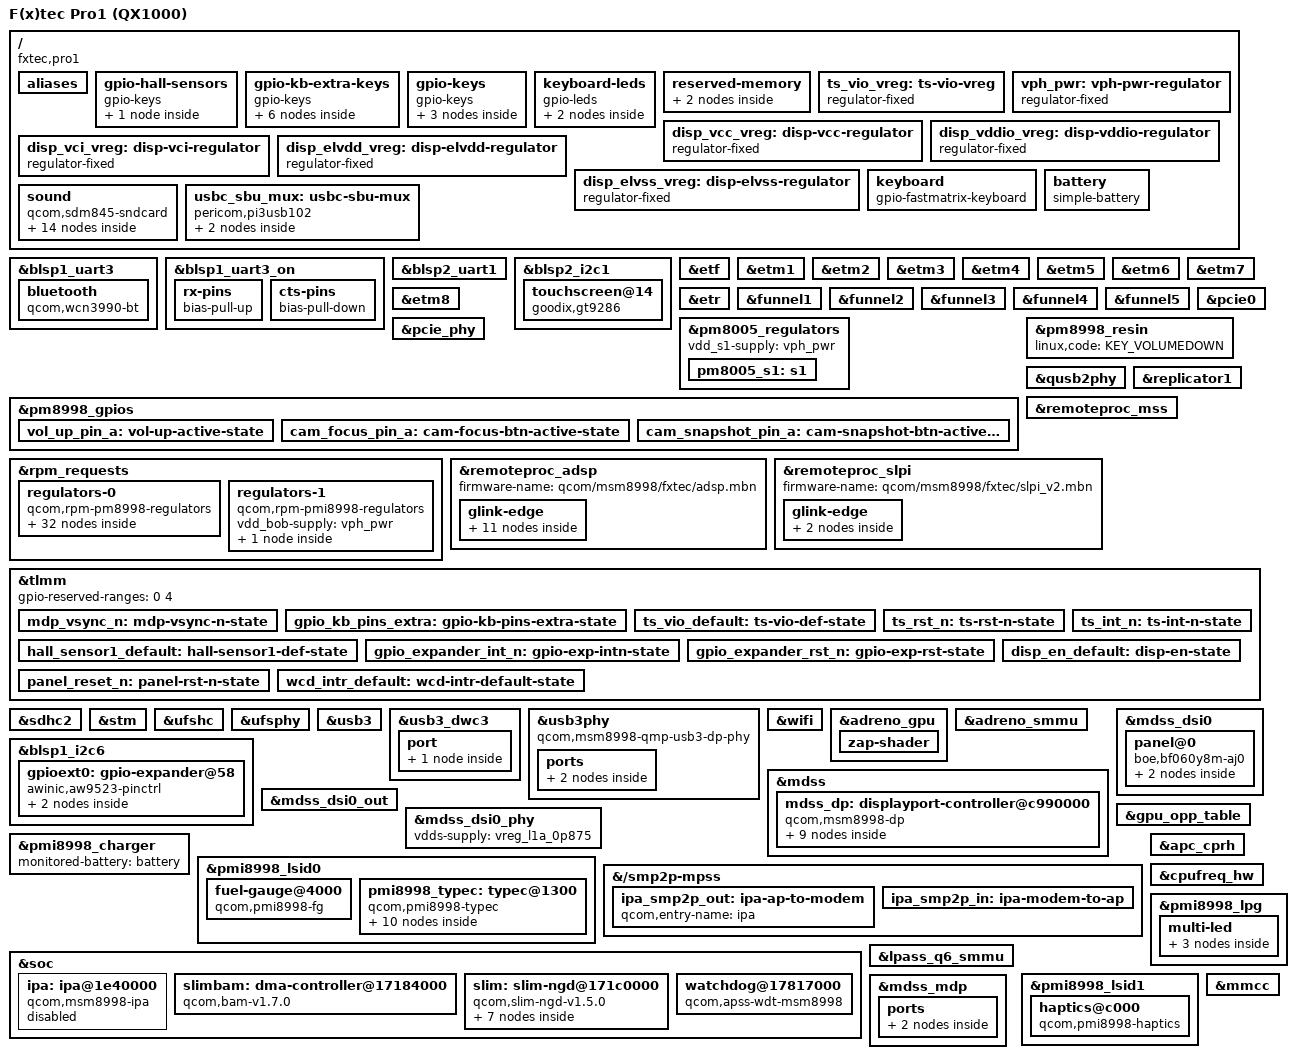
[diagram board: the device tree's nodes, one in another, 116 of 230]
// SPDX-License-Identifier: BSD-3-Clause
/*
 * Copyright (c) 2021, AngeloGioacchino Del Regno
 *                     <angelogioacchino.delregno@somainline.org>
 */

/dts-v1/;

#include <dt-bindings/input/input.h>
#include <dt-bindings/leds/common.h>
#include <dt-bindings/pinctrl/qcom,pmic-gpio.h>
#include "msm8998.dtsi"
#include "pm8005.dtsi"
#include "pm8998.dtsi"
#include "pmi8998.dtsi"

/ {
	model = "F(x)tec Pro1 (QX1000)";
	compatible = "fxtec,pro1", "qcom,msm8998";
	chassis-type = "handset";
	qcom,board-id = <0x02000b 0x10>;

	aliases {
		serial0 = &blsp2_uart1;
		serial1 = &blsp1_uart3;
	};

	/*
	 * Until we hook up type-c detection, we
	 * have to stick with this. But it works.
	 */
	extcon_usb: extcon-usb {
		compatible = "linux,extcon-usb-gpio";
		id-gpios = <&tlmm 38 GPIO_ACTIVE_HIGH>;
	};

	gpio-hall-sensors {
		compatible = "gpio-keys";
		label = "Hall sensors";
		pinctrl-names = "default";
		pinctrl-0 = <&hall_sensor1_default>;

		event-hall-sensor1 {
			label = "Keyboard Hall Sensor";
			gpios = <&tlmm 124 GPIO_ACTIVE_HIGH>;
			debounce-interval = <15>;
			wakeup-source;
			linux,input-type = <EV_SW>;
			linux,code = <SW_KEYPAD_SLIDE>;
		};
	};

	gpio-kb-extra-keys {
		compatible = "gpio-keys";
		label = "Keyboard extra keys";
		pinctrl-names = "default";
		pinctrl-0 = <&gpio_kb_pins_extra>;

		key-home {
			label = "Home";
			gpios = <&tlmm 21 GPIO_ACTIVE_LOW>;
			linux,code = <KEY_HOMEPAGE>;
			debounce-interval = <15>;
			linux,can-disable;
		};

		key-super-l {
			label = "Super Left";
			gpios = <&tlmm 32 GPIO_ACTIVE_LOW>;
			linux,code = <KEY_FN>;
			debounce-interval = <15>;
			linux,can-disable;
		};

		key-super-r {
			label = "Super Right";
			gpios = <&tlmm 33 GPIO_ACTIVE_LOW>;
			linux,code = <KEY_FN>;
			debounce-interval = <15>;
			linux,can-disable;
		};

		key-shift {
			label = "Shift";
			gpios = <&tlmm 114 GPIO_ACTIVE_LOW>;
			linux,code = <KEY_RIGHTSHIFT>;
			debounce-interval = <15>;
			linux,can-disable;
		};

		key-ctrl {
			label = "Ctrl";
			gpios = <&tlmm 128 GPIO_ACTIVE_LOW>;
			linux,code = <KEY_LEFTCTRL>;
			debounce-interval = <15>;
			linux,can-disable;
		};

		key-alt {
			label = "Alt";
			gpios = <&tlmm 129 GPIO_ACTIVE_LOW>;
			linux,code = <KEY_LEFTALT>;
			debounce-interval = <15>;
			linux,can-disable;
		};
	};

	gpio-keys {
		compatible = "gpio-keys";
		label = "Side buttons";
		pinctrl-names = "default";
		pinctrl-0 = <&vol_up_pin_a>, <&cam_focus_pin_a>,
			    <&cam_snapshot_pin_a>;
		button-vol-up {
			label = "Volume Up";
			gpios = <&pm8998_gpios 6 GPIO_ACTIVE_LOW>;
			linux,input-type = <EV_KEY>;
			linux,code = <KEY_VOLUMEUP>;
			wakeup-source;
			debounce-interval = <15>;
		};

		button-camera-snapshot {
			label = "Camera Snapshot";
			gpios = <&pm8998_gpios 7 GPIO_ACTIVE_LOW>;
			linux,input-type = <EV_KEY>;
			linux,code = <KEY_CAMERA>;
			debounce-interval = <15>;
		};

		button-camera-focus {
			label = "Camera Focus";
			gpios = <&pm8998_gpios 8 GPIO_ACTIVE_LOW>;
			linux,input-type = <EV_KEY>;
			linux,code = <KEY_CAMERA_FOCUS>;
			debounce-interval = <15>;
		};
	};

	keyboard-leds {
		compatible = "gpio-leds";

		led-0 {
			color = <LED_COLOR_ID_WHITE>;
			default-state = "off";
			function = LED_FUNCTION_KBD_BACKLIGHT;
			gpios = <&tlmm 16 GPIO_ACTIVE_HIGH>;
			label = "white:kbd_backlight";
			retain-state-suspended;
		};

		led-1 {
			color = <LED_COLOR_ID_YELLOW>;
			default-state = "off";
			function = LED_FUNCTION_CAPSLOCK;
			gpios = <&tlmm 26 GPIO_ACTIVE_HIGH>;
			label = "yellow:capslock";
			linux,default-trigger = "kbd-capslock";
		};
	};

	reserved-memory {
		cont_splash_mem: memory@9d400000 {
			reg = <0x0 0x9d400000 0x0 0x2000000>;
			no-map;
		};

		zap_shader_region: memory@f6400000 {
			compatible = "shared-dma-pool";
			reg = <0x0 0xf6400000 0x0 0x2000>;
			no-map;
		};

		ramoops@ffc00000 {
			compatible = "ramoops";
			reg = <0x0 0xffc00000 0x0 0x100000>;
			console-size = <0x60000>;
			ecc-size = <16>;
			ftrace-size = <0x10000>;
			pmsg-size = <0x20000>;
			record-size = <0x10000>;
		};
	};

	ts_vio_vreg: ts-vio-vreg {
		compatible = "regulator-fixed";
		regulator-name = "ts_vio_reg";
		startup-delay-us = <2>;
		enable-active-high;
		gpio = <&tlmm 81 GPIO_ACTIVE_HIGH>;
		pinctrl-names = "default";
		pinctrl-0 = <&ts_vio_default>;
		regulator-always-on;
	};

	vph_pwr: vph-pwr-regulator {
		compatible = "regulator-fixed";
		regulator-name = "vph_pwr";
		regulator-always-on;
		regulator-boot-on;
	};
};

&blsp1_uart3 {
	status = "okay";

	bluetooth {
		compatible = "qcom,wcn3990-bt";

		vddio-supply = <&vreg_s4a_1p8>;
		vddxo-supply = <&vreg_l7a_1p8>;
		vddrf-supply = <&vreg_l17a_1p3>;
		vddch0-supply = <&vreg_l25a_3p3>;
		max-speed = <3200000>;
	};
};

&blsp1_uart3_on {
	rx-pins {
		/delete-property/ bias-disable;
		/*
		 * Configure a pull-up on 45 (RX). This is needed to
		 * avoid garbage data when the TX pin of the Bluetooth
		 * module is in tri-state (module powered off or not
		 * driving the signal yet).
		 */
		bias-pull-up;
	};

	cts-pins {
		/delete-property/ bias-disable;
		/*
		 * Configure a pull-down on 47 (CTS) to match the pull
		 * of the Bluetooth module.
		 */
		bias-pull-down;
	};
};

&blsp2_uart1 {
	status = "okay";
};

&blsp2_i2c1 {
	status = "okay";

	touchscreen@14 {
		compatible = "goodix,gt9286";
		reg = <0x14>;
		interrupt-parent = <&tlmm>;
		interrupts = <125 IRQ_TYPE_LEVEL_LOW>;
		reset-gpios = <&tlmm 89 GPIO_ACTIVE_LOW>;
		AVDD28-supply = <&vreg_l28_3p0>;
		VDDIO-supply = <&ts_vio_vreg>;
		pinctrl-names = "active";
		pinctrl-0 = <&ts_rst_n>, <&ts_int_n>;
	};
};

&etf {
	status = "okay";
};

&etm1 {
	status = "okay";
};

&etm2 {
	status = "okay";
};

&etm3 {
	status = "okay";
};

&etm4 {
	status = "okay";
};

&etm5 {
	status = "okay";
};

&etm6 {
	status = "okay";
};

&etm7 {
	status = "okay";
};

&etm8 {
	status = "okay";
};

&etr {
	status = "okay";
};

&funnel1 {
	status = "okay";
};

&funnel2 {
	status = "okay";
};

&funnel3 {
	status = "okay";
};

&funnel4 {
	/* FIXME: Figure out why clock late_initcall crashes the board with this enabled. */
};

&funnel5 {
	/* FIXME: Figure out why clock late_initcall crashes the board with this enabled. */
};

&pcie0 {
	status = "okay";
};

&pcie_phy {
	status = "okay";
};

&pm8005_regulators {
	vdd_s1-supply = <&vph_pwr>;

	pm8005_s1: s1 { /* VDD_GFX supply */
		regulator-min-microvolt = <524000>;
		regulator-max-microvolt = <1100000>;
		regulator-enable-ramp-delay = <500>;

		/* Hack until we rig up the gpu consumer */
		regulator-always-on;
	};
};

&pm8998_gpios {
	vol_up_pin_a: vol-up-active-state {
		pins = "gpio6";
		function = "normal";
		bias-pull-up;
		input-enable;
		qcom,drive-strength = <PMIC_GPIO_STRENGTH_NO>;
	};

	cam_focus_pin_a: cam-focus-btn-active-state {
		pins = "gpio7";
		function = "normal";
		bias-pull-up;
		input-enable;
		qcom,drive-strength = <PMIC_GPIO_STRENGTH_NO>;
	};

	cam_snapshot_pin_a: cam-snapshot-btn-active-state {
		pins = "gpio8";
		function = "normal";
		bias-pull-up;
		input-enable;
		qcom,drive-strength = <PMIC_GPIO_STRENGTH_NO>;
	};
};

&pm8998_resin {
	linux,code = <KEY_VOLUMEDOWN>;
	status = "okay";
};

&qusb2phy {
	status = "okay";

	vdd-supply = <&vreg_l1a_0p875>;
	vdda-pll-supply = <&vreg_l12a_1p8>;
	vdda-phy-dpdm-supply = <&vreg_l24a_3p075>;
};

&replicator1 {
	status = "okay";
};

&rpm_requests {
	regulators-0 {
		compatible = "qcom,rpm-pm8998-regulators";

		vdd_s1-supply = <&vph_pwr>;
		vdd_s2-supply = <&vph_pwr>;
		vdd_s3-supply = <&vph_pwr>;
		vdd_s4-supply = <&vph_pwr>;
		vdd_s5-supply = <&vph_pwr>;
		vdd_s6-supply = <&vph_pwr>;
		vdd_s7-supply = <&vph_pwr>;
		vdd_s8-supply = <&vph_pwr>;
		vdd_s9-supply = <&vph_pwr>;
		vdd_s10-supply = <&vph_pwr>;
		vdd_s11-supply = <&vph_pwr>;
		vdd_s12-supply = <&vph_pwr>;
		vdd_s13-supply = <&vph_pwr>;
		vdd_l1_l27-supply = <&vreg_s7a_1p025>;
		vdd_l2_l8_l17-supply = <&vreg_s3a_1p35>;
		vdd_l3_l11-supply = <&vreg_s7a_1p025>;
		vdd_l4_l5-supply = <&vreg_s7a_1p025>;
		vdd_l6-supply = <&vreg_s5a_2p04>;
		vdd_l7_l12_l14_l15-supply = <&vreg_s5a_2p04>;
		vdd_l9-supply = <&vreg_bob>;
		vdd_l10_l23_l25-supply = <&vreg_bob>;
		vdd_l13_l19_l21-supply = <&vreg_bob>;
		vdd_l16_l28-supply = <&vreg_bob>;
		vdd_l18_l22-supply = <&vreg_bob>;
		vdd_l20_l24-supply = <&vreg_bob>;
		vdd_l26-supply = <&vreg_s3a_1p35>;
		vdd_lvs1_lvs2-supply = <&vreg_s4a_1p8>;

		vreg_s3a_1p35: s3 {
			regulator-min-microvolt = <1352000>;
			regulator-max-microvolt = <1352000>;
		};

		vreg_s4a_1p8: s4 {
			regulator-min-microvolt = <1800000>;
			regulator-max-microvolt = <1800000>;
			regulator-allow-set-load;
		};

		vreg_s5a_2p04: s5 {
			regulator-min-microvolt = <1904000>;
			regulator-max-microvolt = <2040000>;
		};

		vreg_s7a_1p025: s7 {
			regulator-min-microvolt = <900000>;
			regulator-max-microvolt = <1028000>;
		};

		vreg_l1a_0p875: l1 {
			regulator-min-microvolt = <880000>;
			regulator-max-microvolt = <880000>;
		};

		vreg_l2a_1p2: l2 {
			regulator-min-microvolt = <1200000>;
			regulator-max-microvolt = <1200000>;
		};

		vreg_l3a_1p0: l3 {
			regulator-min-microvolt = <1000000>;
			regulator-max-microvolt = <1000000>;
		};

		vreg_l5a_0p8: l5 {
			regulator-min-microvolt = <800000>;
			regulator-max-microvolt = <800000>;
		};

		vreg_l6a_1p8: l6 {
			regulator-min-microvolt = <1808000>;
			regulator-max-microvolt = <1808000>;
		};

		vreg_l7a_1p8: l7 {
			regulator-min-microvolt = <1800000>;
			regulator-max-microvolt = <1800000>;
		};

		vreg_l8a_1p2: l8 {
			regulator-min-microvolt = <1200000>;
			regulator-max-microvolt = <1200000>;
		};

		vreg_l9a_1p8: l9 {
			regulator-min-microvolt = <1808000>;
			regulator-max-microvolt = <2960000>;
		};

		vreg_l10a_1p8: l10 {
			regulator-min-microvolt = <1808000>;
			regulator-max-microvolt = <2960000>;
		};

		vreg_l11a_1p0: l11 {
			regulator-min-microvolt = <1000000>;
			regulator-max-microvolt = <1000000>;
		};

		vreg_l12a_1p8: l12 {
			regulator-min-microvolt = <1800000>;
			regulator-max-microvolt = <1800000>;
		};

		vreg_l13a_2p95: l13 {
			regulator-min-microvolt = <1808000>;
			regulator-max-microvolt = <2960000>;
		};

		vreg_l14a_1p88: l14 {
			regulator-min-microvolt = <1880000>;
			regulator-max-microvolt = <1880000>;
		};

		vreg_l15a_1p8: l15 {
			regulator-min-microvolt = <1800000>;
			regulator-max-microvolt = <1800000>;
		};

		vreg_l16a_2p7: l16 {
			regulator-min-microvolt = <2704000>;
			regulator-max-microvolt = <2704000>;
		};

		vreg_l17a_1p3: l17 {
			regulator-min-microvolt = <1304000>;
			regulator-max-microvolt = <1304000>;
		};

		vreg_l18a_2p7: l18 {
			regulator-min-microvolt = <2704000>;
			regulator-max-microvolt = <2704000>;
		};

		vreg_l19a_3p0: l19 {
			regulator-min-microvolt = <3008000>;
			regulator-max-microvolt = <3008000>;
		};

		vreg_l20a_2p95: l20 {
			regulator-min-microvolt = <2960000>;
			regulator-max-microvolt = <2960000>;
			regulator-allow-set-load;
		};

		vreg_l21a_2p95: l21 {
			regulator-min-microvolt = <2960000>;
			regulator-max-microvolt = <2960000>;
			regulator-system-load = <800000>;
			regulator-allow-set-load;
		};

		vreg_l22a_2p85: l22 {
			regulator-min-microvolt = <2864000>;
			regulator-max-microvolt = <2864000>;
		};

		vreg_l23a_3p3: l23 {
			regulator-min-microvolt = <3312000>;
			regulator-max-microvolt = <3312000>;
		};

		vreg_l24a_3p075: l24 {
			regulator-min-microvolt = <3088000>;
			regulator-max-microvolt = <3088000>;
		};

		vreg_l25a_3p3: l25 {
			regulator-min-microvolt = <3104000>;
			regulator-max-microvolt = <3312000>;
		};

		vreg_l26a_1p2: l26 {
			regulator-min-microvolt = <1200000>;
			regulator-max-microvolt = <1200000>;
			regulator-allow-set-load;
		};

		vreg_l28_3p0: l28 {
			regulator-min-microvolt = <3008000>;
			regulator-max-microvolt = <3008000>;
		};

		vreg_lvs1a_1p8: lvs1 {
			regulator-min-microvolt = <1800000>;
			regulator-max-microvolt = <1800000>;
		};

		vreg_lvs2a_1p8: lvs2 {
			regulator-min-microvolt = <1800000>;
			regulator-max-microvolt = <1800000>;
		};

	};

	regulators-1 {
		compatible = "qcom,rpm-pmi8998-regulators";

		vdd_bob-supply = <&vph_pwr>;

		vreg_bob: bob {
			regulator-min-microvolt = <3312000>;
			regulator-max-microvolt = <3600000>;
		};
	};
};

&remoteproc_adsp {
	status = "okay";
};

&remoteproc_mss {
	status = "okay";
};

&remoteproc_slpi {
	status = "okay";
};

&tlmm {
	gpio-reserved-ranges = <0 4>;

	mdp_vsync_n: mdp-vsync-n-state {
		pins = "gpio10";
		function = "mdp_vsync_a";
		bias-pull-down;
		drive-strength = <2>;
	};

	gpio_kb_pins_extra: gpio-kb-pins-extra-state {
		pins = "gpio21", "gpio32", "gpio33", "gpio114",
		       "gpio128", "gpio129";
		function = "gpio";
		drive-strength = <2>;
		bias-pull-up;
	};

	ts_vio_default: ts-vio-def-state {
		pins = "gpio81";
		function = "gpio";
		bias-disable;
		drive-strength = <2>;
	};

	ts_rst_n: ts-rst-n-state {
		pins = "gpio89";
		function = "gpio";
		bias-pull-up;
		drive-strength = <8>;
	};

	hall_sensor1_default: hall-sensor1-def-state {
		pins = "gpio124";
		function = "gpio";
		bias-disable;
		drive-strength = <2>;
	};

	ts_int_n: ts-int-n-state {
		pins = "gpio125";
		function = "gpio";
		bias-disable;
		drive-strength = <8>;
	};
};

&sdhc2 {
	status = "okay";
	cd-gpios = <&tlmm 95 GPIO_ACTIVE_LOW>;

	vmmc-supply = <&vreg_l21a_2p95>;
	vqmmc-supply = <&vreg_l13a_2p95>;

	pinctrl-names = "default", "sleep";
	pinctrl-0 = <&sdc2_on &sdc2_cd>;
	pinctrl-1 = <&sdc2_off &sdc2_cd>;
};

&stm {
	status = "okay";
};

&ufshc {
	status = "okay";
	vcc-supply = <&vreg_l20a_2p95>;
	vccq-supply = <&vreg_l26a_1p2>;
	vccq2-supply = <&vreg_s4a_1p8>;
	vdd-hba-supply = <&vreg_l26a_1p2>;
	vcc-max-microamp = <750000>;
	vccq-max-microamp = <560000>;
	vccq2-max-microamp = <750000>;
};

&ufsphy {
	status = "okay";
	vdda-phy-supply = <&vreg_l1a_0p875>;
	vdda-pll-supply = <&vreg_l2a_1p2>;
};

&usb3 {
	status = "okay";
};

&usb3_dwc3 {
	dr_mode = "peripheral";
	extcon = <&extcon_usb>;
};

&usb3phy {
	status = "okay";

	vdda-phy-supply = <&vreg_l1a_0p875>;
	vdda-pll-supply = <&vreg_l2a_1p2>;
};

/* GT9286 analog supply */
&vreg_l28_3p0 {
	regulator-min-microvolt = <2800000>;
	regulator-max-microvolt = <2800000>;
};

&wifi {
	status = "okay";

	vdd-0.8-cx-mx-supply = <&vreg_l5a_0p8>;
	vdd-1.8-xo-supply = <&vreg_l7a_1p8>;
	vdd-1.3-rfa-supply = <&vreg_l17a_1p3>;
	vdd-3.3-ch0-supply = <&vreg_l25a_3p3>;
};

/*
 * Pro1 additions on top of mainline msm8998-fxtec-pro1.dts:
 * display (BOE BF060Y8M-AJ0 on DSI0), Adreno 540, hardware keyboard
 * (AW9523B expander + gpio-fastmatrix), remoteproc firmware paths.
 * Forward-ported from gitlab.com/msm8998-mainline/linux (master).
 */

/ {
	/* Panel rails are switched on by the bootloader and never touched again */
	disp_vcc_vreg: disp-vcc-regulator {
		compatible = "regulator-fixed";
		regulator-name = "disp_vcc";
		regulator-min-microvolt = <3300000>;
		regulator-max-microvolt = <3300000>;
		regulator-boot-on;
		regulator-always-on;
	};

	disp_vddio_vreg: disp-vddio-regulator {
		compatible = "regulator-fixed";
		regulator-name = "disp_vddio";
		regulator-min-microvolt = <1800000>;
		regulator-max-microvolt = <1800000>;
		regulator-boot-on;
		regulator-always-on;
	};

	disp_vci_vreg: disp-vci-regulator {
		compatible = "regulator-fixed";
		regulator-name = "disp_vci";
		regulator-min-microvolt = <3000000>;
		regulator-max-microvolt = <3000000>;
		regulator-boot-on;
		regulator-always-on;
	};

	disp_elvdd_vreg: disp-elvdd-regulator {
		compatible = "regulator-fixed";
		regulator-name = "disp_elvdd";
		regulator-min-microvolt = <4600000>;
		regulator-max-microvolt = <4600000>;
		regulator-boot-on;
		regulator-always-on;
	};

	disp_elvss_vreg: disp-elvss-regulator {
		compatible = "regulator-fixed";
		regulator-name = "disp_elvss";
		regulator-min-microvolt = <2400000>;
		regulator-max-microvolt = <2400000>;
		regulator-boot-on;
		regulator-always-on;
	};

	keyboard {
		compatible = "gpio-fastmatrix-keyboard";
		label = "F(x)tec Pro1 Hardware Keyboard";

		row-gpios = <&gpioext0 0 (GPIO_ACTIVE_LOW | GPIO_OPEN_DRAIN)>,
			    <&gpioext0 1 (GPIO_ACTIVE_LOW | GPIO_OPEN_DRAIN)>,
			    <&gpioext0 2 (GPIO_ACTIVE_LOW | GPIO_OPEN_DRAIN)>,
			    <&gpioext0 3 (GPIO_ACTIVE_LOW | GPIO_OPEN_DRAIN)>,
			    <&gpioext0 4 (GPIO_ACTIVE_LOW | GPIO_OPEN_DRAIN)>,
			    <&gpioext0 5 (GPIO_ACTIVE_LOW | GPIO_OPEN_DRAIN)>,
			    <&gpioext0 6 (GPIO_ACTIVE_LOW | GPIO_OPEN_DRAIN)>,
			    <&gpioext0 7 (GPIO_ACTIVE_LOW | GPIO_OPEN_DRAIN)>;
		col-gpios = <&gpioext0 8 GPIO_ACTIVE_LOW>,
			    <&gpioext0 9 GPIO_ACTIVE_LOW>,
			    <&gpioext0 10 GPIO_ACTIVE_LOW>,
			    <&gpioext0 11 GPIO_ACTIVE_LOW>,
			    <&gpioext0 12 GPIO_ACTIVE_LOW>,
			    <&gpioext0 13 GPIO_ACTIVE_LOW>,
			    <&gpioext0 14 GPIO_ACTIVE_LOW>,
			    <&gpioext0 15 GPIO_ACTIVE_LOW>;

		pinctrl-names = "default";
		pinctrl-0 = <&keyboard_pins_col>, <&keyboard_pins_row>;

		/*
		 * A change is reported once two consecutive scans agree, so the time to
		 * register a press is ~2 x (debounce + scan). With 1500 us per column
		 * (12 ms per scan) a fast tap fell between scans and was dropped; the
		 * AW9523 I2C round trips already give each column a few hundred us.
		 */
		autorescan-ms = <5>;
		debounce-delay-ms = <2>;
		col-scan-delay-us = <100>;

		linux,keymap = <
			MATRIX_KEY(0, 0, KEY_F1)	MATRIX_KEY(1, 0, KEY_H)
			MATRIX_KEY(2, 0, KEY_B)		MATRIX_KEY(3, 0, KEY_7)
			MATRIX_KEY(4, 0, KEY_UP)	MATRIX_KEY(5, 0, KEY_ENTER)
			MATRIX_KEY(6, 0, KEY_Y)		MATRIX_KEY(7, 0, KEY_COMMA)
			MATRIX_KEY(0, 1, KEY_3)		MATRIX_KEY(1, 1, KEY_S)
			MATRIX_KEY(2, 1, KEY_Z)		MATRIX_KEY(3, 1, KEY_M)
			MATRIX_KEY(4, 1, KEY_I)		MATRIX_KEY(5, 1, KEY_9)
			MATRIX_KEY(6, 1, KEY_W)		MATRIX_KEY(7, 1, KEY_J)
			MATRIX_KEY(0, 2, KEY_LEFT)	MATRIX_KEY(1, 2, KEY_G)
			MATRIX_KEY(2, 2, KEY_V)		MATRIX_KEY(3, 2, KEY_6)
			MATRIX_KEY(4, 2, KEY_RIGHT)	MATRIX_KEY(5, 2, KEY_DELETE)
			MATRIX_KEY(6, 2, KEY_T)		MATRIX_KEY(7, 2, KEY_DOT)
			MATRIX_KEY(0, 3, KEY_SLASH)	MATRIX_KEY(1, 3, KEY_A)
			MATRIX_KEY(2, 3, KEY_RIGHTBRACE) MATRIX_KEY(3, 3, KEY_HOMEPAGE)
			MATRIX_KEY(4, 3, KEY_P)		MATRIX_KEY(5, 3, KEY_MINUS)
			MATRIX_KEY(6, 3, KEY_Q)		MATRIX_KEY(7, 3, KEY_L)
			MATRIX_KEY(0, 4, KEY_BACKSPACE)	MATRIX_KEY(1, 4, KEY_D)
			MATRIX_KEY(2, 4, KEY_X)		MATRIX_KEY(3, 4, KEY_K)
			MATRIX_KEY(4, 4, KEY_SEMICOLON)	MATRIX_KEY(5, 4, KEY_EQUAL)
			MATRIX_KEY(6, 4, KEY_E)		MATRIX_KEY(7, 4, KEY_APOSTROPHE)
			MATRIX_KEY(0, 5, KEY_CAPSLOCK)	MATRIX_KEY(1, 5, KEY_BACKSLASH)
			MATRIX_KEY(2, 5, KEY_LEFTBRACE)	MATRIX_KEY(3, 5, KEY_DOWN)
			MATRIX_KEY(4, 5, KEY_O)		MATRIX_KEY(5, 5, KEY_0)
			MATRIX_KEY(6, 5, KEY_GRAVE)	MATRIX_KEY(7, 5, KEY_K)
			MATRIX_KEY(0, 6, KEY_SPACE)	MATRIX_KEY(1, 6, KEY_F)
			MATRIX_KEY(2, 6, KEY_C)		MATRIX_KEY(3, 6, KEY_N)
			MATRIX_KEY(4, 6, KEY_U)		MATRIX_KEY(5, 6, KEY_8)
			MATRIX_KEY(6, 6, KEY_R)		MATRIX_KEY(7, 6, KEY_5)
			MATRIX_KEY(0, 7, KEY_ESC)	MATRIX_KEY(1, 7, KEY_1)
			MATRIX_KEY(2, 7, KEY_RESERVED)	MATRIX_KEY(3, 7, KEY_RESERVED)
			MATRIX_KEY(4, 7, KEY_2)		MATRIX_KEY(5, 7, KEY_4)
			MATRIX_KEY(6, 7, KEY_TAB)	MATRIX_KEY(7, 7, KEY_RESERVED)
		>;
	};
};

&adreno_gpu {
	status = "okay";

	zap-shader {
		memory-region = <&zap_shader_region>;
		firmware-name = "qcom/msm8998/fxtec/a540_zap.mbn";
	};
};

&adreno_smmu {
	status = "okay";
};

/* ponytail: GFX rail pinned high until GPU CPR is wired up (costs idle power) */
&pm8005_s1 {
	regulator-min-microvolt = <988000>;
	regulator-max-microvolt = <1100000>;
};

&blsp1_i2c6 {
	status = "okay";

	gpioext0: gpio-expander@58 {
		compatible = "awinic,aw9523-pinctrl";
		reg = <0x58>;
		interrupt-parent = <&tlmm>;
		/*
		 * Edge, not the stock level-low: with the mainline aw9523 driver a
		 * level trigger storms (INTN does not clear). The pin needs its
		 * pull-up though (see gpio_expander_int_n); with the inherited
		 * pull-down the edges were marginal and the keyboard died.
		 */
		interrupts = <50 IRQ_TYPE_EDGE_FALLING>;
		reset-gpios = <&tlmm 51 GPIO_ACTIVE_HIGH>;

		gpio-controller;
		#gpio-cells = <2>;
		gpio-ranges = <&gpioext0 0 0 16>;
		interrupt-controller;
		#interrupt-cells = <2>;

		pinctrl-names = "default";
		pinctrl-0 = <&gpio_expander_int_n>, <&gpio_expander_rst_n>;

		keyboard_pins_col: keyboard-matrix-col-pins {
			pins = "gpio8", "gpio9", "gpio10", "gpio11",
			       "gpio12", "gpio13", "gpio14", "gpio15";
			function = "gpio";
			output-low;
		};

		keyboard_pins_row: keyboard-matrix-row-pins {
			pins = "gpio0", "gpio1", "gpio2", "gpio3",
			       "gpio4", "gpio5", "gpio6", "gpio7";
			function = "gpio";
			drive-open-drain;
			input-enable;
		};
	};
};

&mdss {
	status = "okay";
};

&mdss_dsi0 {
	vdd-supply = <&vreg_l1a_0p875>;
	vdda-supply = <&vreg_l2a_1p2>;
	status = "okay";

	panel@0 {
		compatible = "boe,bf060y8m-aj0";
		reg = <0>;

		reset-gpios = <&tlmm 94 GPIO_ACTIVE_LOW>;
		/* Landscape with the keyboard out: the panel top (earpiece) is on the left */
		rotation = <90>;

		vcc-supply = <&disp_vcc_vreg>;
		vddio-supply = <&disp_vddio_vreg>;
		vci-supply = <&disp_vci_vreg>;
		elvdd-supply = <&disp_elvdd_vreg>;
		elvss-supply = <&disp_elvss_vreg>;

		pinctrl-names = "default";
		pinctrl-0 = <&panel_reset_n &disp_en_default &mdp_vsync_n>;

		port {
			panel_in: endpoint {
				remote-endpoint = <&mdss_dsi0_out>;
			};
		};
	};
};

&mdss_dsi0_out {
	remote-endpoint = <&panel_in>;
	data-lanes = <0 1 2 3>;
};

&mdss_dsi0_phy {
	vdds-supply = <&vreg_l1a_0p875>;
	status = "okay";
};

&remoteproc_adsp {
	firmware-name = "qcom/msm8998/fxtec/adsp.mbn";
};

&remoteproc_mss {
	firmware-name = "qcom/msm8998/fxtec/mba.mbn", "qcom/msm8998/fxtec/modem.mbn";
};

&remoteproc_slpi {
	firmware-name = "qcom/msm8998/fxtec/slpi_v2.mbn";
};

&tlmm {
	gpio_expander_int_n: gpio-exp-intn-state {
		pins = "gpio50";
		function = "gpio";
		drive-strength = <2>;
		bias-pull-up;	/* open-drain, active-low INTN */
	};

	gpio_expander_rst_n: gpio-exp-rst-state {
		pins = "gpio51";
		function = "gpio";
		drive-strength = <8>;
	};

	disp_en_default: disp-en-state {
		pins = "gpio62";
		function = "gpio";
		drive-strength = <8>;
		bias-disable;
	};

	panel_reset_n: panel-rst-n-state {
		pins = "gpio94";
		function = "gpio";
		drive-strength = <8>;
		bias-disable;
	};
};

/*
 * USB 3 SuperSpeed: the QMP USB-C PHY flips its lanes for a reversed plug when
 * told the orientation. The charger (qcom_smbx, patch 0052) reads it from the
 * PMI8998 Type-C status and drives this orientation switch.
 */
&usb3phy {
	orientation-switch;
};


/*
 * Touch: the goodix driver drives reset in raw levels (0 = in reset), and with
 * the INT gpio available it resets the controller at probe and writes
 * goodix_9286_cfg.bin (the Pro1's own config from the stock kernel's DT),
 * like the stock gt1x driver did. Without it the panel runs whatever config
 * the controller holds: jumpy, ghost touches.
 */
&blsp2_i2c1 {
	touchscreen@14 {
		reset-gpios = <&tlmm 89 GPIO_ACTIVE_HIGH>;
		irq-gpios = <&tlmm 125 GPIO_ACTIVE_HIGH>;
	};
};

/*
 * Battery: PMI8998 fuel gauge (qcom_fg). Second reg is the charger block it
 * reads charging status from. Values from postmarketOS' Pro1 port; 3150 mAh,
 * 4.4 V max as the stock t5-1-batterydata-qrd-skuk-3150mah profile.
 * The SMB2 charger (qcom_smbx: charger type detection, input current limit,
 * fast charge capped at 1 A) owns the usb-plugin interrupt.
 */
/ {
	battery: battery {
		compatible = "simple-battery";
		charge-full-design-microamp-hours = <3150000>;
		voltage-min-design-microvolt = <3400000>;
		voltage-max-design-microvolt = <4400000>;
	};
};

&pmi8998_charger {
	monitored-battery = <&battery>;
	orientation-switch = <&usb3phy>;
	status = "okay";
};

&pmi8998_lsid0 {
	fuel-gauge@4000 {
		compatible = "qcom,pmi8998-fg";
		reg = <0x4000>, <0x1000>;
		qcom,min-voltage-uv = <3700000>;
		qcom,max-voltage-uv = <4400000>;
		qcom,battery-capacity-ua = <3150000>;
	};
};

/*
 * ponytail: no GPU CPR upstream, the GFX rail sits at a fixed 988 mV and the
 * top OPPs fault under KWin (gpu fault -> hangcheck -> SoC dies). Cap at 414 MHz
 * until GFX voltage scaling is wired up.
 */
&gpu_opp_table {
	/delete-node/ opp-710000097;
	/delete-node/ opp-670000048;
	/delete-node/ opp-596000097;
	/delete-node/ opp-515000097;
};

/*
 * ponytail: no ramoops. Neither the mainline 0xffc00000 nor the stock 0xac000000
 * region is reserved in the UEFI memory map, so a KASLR'd kernel can land on it
 * and ramoops init corrupts kernel text. Re-add once UEFI reserves a region.
 */
/ {
	reserved-memory {
		/delete-node/ ramoops@ffc00000;
	};
};

/*
 * IPA v3.1: modem data path (rmnet over IPA) for cellular data. Not in
 * msm8998.dtsi; layout from the sdm845 node, SIDs/IRQs from the stock Pro1 DT.
 * The AP loads the GSI firmware itself (stock: PIL "ipa_fws").
 */
&{/smp2p-mpss} {
	ipa_smp2p_out: ipa-ap-to-modem {
		qcom,entry-name = "ipa";
		#qcom,smem-state-cells = <1>;
	};

	ipa_smp2p_in: ipa-modem-to-ap {
		qcom,entry-name = "ipa";
		interrupt-controller;
		#interrupt-cells = <2>;
	};
};

&soc {
	ipa: ipa@1e40000 {
		compatible = "qcom,msm8998-ipa";
		iommus = <&anoc2_smmu 0x18e0>, <&anoc2_smmu 0x18e2>;
		reg = <0x01e40000 0x7000>,
		      <0x01e47000 0x2000>,
		      <0x01e04000 0x2c000>;
		reg-names = "ipa-reg", "ipa-shared", "gsi";
		interrupts-extended = <&intc GIC_SPI 333 IRQ_TYPE_EDGE_RISING>,
				      <&intc GIC_SPI 432 IRQ_TYPE_LEVEL_HIGH>,
				      <&ipa_smp2p_in 0 IRQ_TYPE_EDGE_RISING>,
				      <&ipa_smp2p_in 1 IRQ_TYPE_EDGE_RISING>;
		interrupt-names = "ipa", "gsi", "ipa-clock-query", "ipa-setup-ready";
		clocks = <&rpmcc RPM_SMD_IPA_CLK>;
		clock-names = "core";
		qcom,smem-states = <&ipa_smp2p_out 0>, <&ipa_smp2p_out 1>;
		qcom,smem-state-names = "ipa-clock-enabled-valid", "ipa-clock-enabled";
		qcom,gsi-loader = "self";
		memory-region = <&ipa_fw_mem>;
		firmware-name = "qcom/msm8998/fxtec/ipa_fws.mbn";

		/*
		 * Set up at boot with the modem off, IPA wedges the SoC ~2 min later
		 * (GPU lockup, CPUs stuck on the bus): 3/3 boots, 0/1 without it.
		 * Also lacks the "interconnects" the binding requires (msm8998 has no
		 * interconnect provider). ponytail: off until cellular control works.
		 */
		status = "disabled";
	};
};

/*
 * Audio: WCD9340 codec on SLIMbus, two WSA881x speaker amps on its SoundWire,
 * all through the ADSP (APR/Q6). msm8998.dtsi has none of it; layout from
 * sdm845 (same codec and amps), SLIMbus from msm8996 (same NGD v1.5.0),
 * addresses, GPIOs, clock and supplies from the stock Pro1 DT.
 */
#include <dt-bindings/soc/qcom,apr.h>
#include <dt-bindings/sound/qcom,q6afe.h>
#include <dt-bindings/sound/qcom,q6asm.h>

&remoteproc_adsp {
	glink-edge {
		apr {
			compatible = "qcom,apr-v2";
			/* LPASS ADSP power domain: nothing else votes it, and it stays off */
			power-domains = <&gcc LPASS_ADSP_GDSC>;
			qcom,glink-channels = "apr_audio_svc";
			qcom,domain = <APR_DOMAIN_ADSP>;
			#address-cells = <1>;
			#size-cells = <0>;
			qcom,intents = <512 20>;
			/*
			 * No qcom,protection-domain (as msm8996): the msm8998 ADSP
			 * answers one PDR listener per service, and SLIMbus needs it.
			 * A second one timed out and tore SLIMbus down.
			 */

			service@3 {
				reg = <APR_SVC_ADSP_CORE>;
				compatible = "qcom,q6core";
			};

			q6afe: service@4 {
				compatible = "qcom,q6afe";
				reg = <APR_SVC_AFE>;

				q6afedai: dais {
					compatible = "qcom,q6afe-dais";
					#address-cells = <1>;
					#size-cells = <0>;
					#sound-dai-cells = <1>;
				};
			};

			q6asm: service@7 {
				compatible = "qcom,q6asm";
				reg = <APR_SVC_ASM>;

				q6asmdai: dais {
					compatible = "qcom,q6asm-dais";
					/*
					 * The DSP reaches its PCM buffers only through the LPASS
					 * SMMU; a raw physical address above 4 GB kills the SoC
					 * on the DSP's first access (porthole-dev msm8998 port).
					 * Translated domain: pro1-audio.conf modprobe hook.
					 */
					iommus = <&lpass_q6_smmu 1>;
					#address-cells = <1>;
					#size-cells = <0>;
					#sound-dai-cells = <1>;

					dai@0 {
						reg = <MSM_FRONTEND_DAI_MULTIMEDIA1>;
					};

					dai@1 {
						reg = <MSM_FRONTEND_DAI_MULTIMEDIA2>;
					};

					dai@2 {
						reg = <MSM_FRONTEND_DAI_MULTIMEDIA3>;
					};
				};
			};

			q6adm: service@8 {
				compatible = "qcom,q6adm";
				reg = <APR_SVC_ADM>;

				q6routing: routing {
					compatible = "qcom,q6adm-routing";
					#sound-dai-cells = <0>;
				};
			};
		};
	};
};

&lpass_q6_smmu {
	status = "okay";
};

&soc {
	slimbam: dma-controller@17184000 {
		compatible = "qcom,bam-v1.7.0";
		qcom,controlled-remotely;
		reg = <0x17184000 0x32000>;
		num-channels = <31>;
		interrupts = <GIC_SPI 164 IRQ_TYPE_LEVEL_HIGH>;
		#dma-cells = <1>;
		qcom,ee = <1>;
		qcom,num-ees = <2>;
	};

	slim: slim-ngd@171c0000 {
		compatible = "qcom,slim-ngd-v1.5.0";
		reg = <0x171c0000 0x2c000>;
		interrupts = <GIC_SPI 163 IRQ_TYPE_LEVEL_HIGH>;
		dmas = <&slimbam 3>, <&slimbam 4>;
		dma-names = "rx", "tx";
		#address-cells = <1>;
		#size-cells = <0>;

		slim@1 {
			reg = <1>;
			#address-cells = <2>;
			#size-cells = <0>;

			wcd9340_ifd: ifd@0,0 {
				compatible = "slim217,250";
				reg = <0 0>;
			};

			wcd9340: codec@1,0 {
				compatible = "slim217,250";
				reg = <1 0>;
				slim-ifc-dev = <&wcd9340_ifd>;
				#sound-dai-cells = <1>;

				interrupts-extended = <&tlmm 54 IRQ_TYPE_LEVEL_HIGH>;
				interrupt-controller;
				#interrupt-cells = <1>;

				clocks = <&rpmcc RPM_SMD_LN_BB_CLK2>;
				clock-names = "extclk";
				#clock-cells = <0>;
				clock-frequency = <9600000>;
				clock-output-names = "mclk";

				reset-gpios = <&tlmm 64 GPIO_ACTIVE_HIGH>;
				pinctrl-0 = <&wcd_intr_default>;
				pinctrl-names = "default";

				vdd-buck-supply = <&vreg_s4a_1p8>;
				vdd-buck-sido-supply = <&vreg_s4a_1p8>;
				vdd-tx-supply = <&vreg_s4a_1p8>;
				vdd-rx-supply = <&vreg_s4a_1p8>;
				vdd-io-supply = <&vreg_s4a_1p8>;

				qcom,micbias1-microvolt = <1800000>;
				qcom,micbias2-microvolt = <1800000>;
				qcom,micbias3-microvolt = <1800000>;
				qcom,micbias4-microvolt = <1800000>;
				/* stock qcom,msm-mbhc-hphl-swh = <1> */
				qcom,hphl-jack-type-normally-closed;
				qcom,mbhc-buttons-vthreshold-microvolt = <75000 150000 237000 500000 500000 500000 500000 500000>;
				qcom,mbhc-headset-vthreshold-microvolt = <1700000>;
				qcom,mbhc-headphone-vthreshold-microvolt = <50000>;

				#address-cells = <1>;
				#size-cells = <1>;

				wcdgpio: gpio-controller@42 {
					compatible = "qcom,wcd9340-gpio";
					gpio-controller;
					#gpio-cells = <2>;
					reg = <0x42 0x2>;
				};

				swm: soundwire@c85 {
					compatible = "qcom,soundwire-v1.3.0";
					reg = <0xc85 0x40>;
					interrupts-extended = <&wcd9340 20>;
					qcom,dout-ports = <6>;
					qcom,din-ports = <2>;
					qcom,ports-sinterval-low = /bits/ 8 <0x07 0x1f 0x3f 0x7 0x1f 0x3f 0x0f 0x0f>;
					qcom,ports-offset1 = /bits/ 8 <0x01 0x02 0x0c 0x6 0x12 0x0d 0x07 0x0a>;
					qcom,ports-offset2 = /bits/ 8 <0x00 0x00 0x1f 0x00 0x00 0x1f 0x00 0x00>;
					#sound-dai-cells = <1>;
					clocks = <&wcd9340>;
					clock-names = "iface";
					#address-cells = <2>;
					#size-cells = <0>;

					/*
					 * The Pro1 swaps the amps' unique IDs (stock: left at
					 * ...0212, right at ...0211). Shutdown lines: stock tavil
					 * "gpio2"/"gpio3", 1-based.
					 */
					right_spkr: speaker@0,1 {
						compatible = "sdw10217201000";
						reg = <0 1>;
						powerdown-gpios = <&wcdgpio 2 GPIO_ACTIVE_HIGH>;
						#thermal-sensor-cells = <0>;
						sound-name-prefix = "SpkrRight";
						#sound-dai-cells = <0>;
					};

					left_spkr: speaker@0,2 {
						compatible = "sdw10217201000";
						reg = <0 2>;
						powerdown-gpios = <&wcdgpio 1 GPIO_ACTIVE_HIGH>;
						#thermal-sensor-cells = <0>;
						sound-name-prefix = "SpkrLeft";
						#sound-dai-cells = <0>;
					};
				};
			};
		};
	};
};

&tlmm {
	wcd_intr_default: wcd-intr-default-state {
		pins = "gpio54";
		function = "gpio";
		bias-pull-down;
		drive-strength = <2>;
	};
};

/ {
	sound {
		compatible = "qcom,sdm845-sndcard";
		model = "F(x)tec Pro1";
		/*
		 * stock QX1000 routing; AMIC2 is the headset mic. MCLK is a supply
		 * widget nothing else pulls up: the mic biases need it too, or
		 * capture records silence (porthole-dev taimen).
		 */
		audio-routing =
			"RX_BIAS", "MCLK",
			"MIC BIAS1", "MCLK",
			"MIC BIAS2", "MCLK",
			"MIC BIAS3", "MCLK",
			"MIC BIAS4", "MCLK",
			"AMIC2", "MIC BIAS2",
			/*
			 * Stock msm8998-audio.dtsi: every analog input sits behind a
			 * mic bias, and each bias pulls up MCLK. Without these an
			 * AMIC capture ran with MCLK off and recorded zeros.
			 */
			"AMIC3", "MIC BIAS2",
			"AMIC4", "MIC BIAS2",
			"AMIC5", "MIC BIAS3",
			/* stock also has AMIC6 -> MIC BIAS4; mainline wcd934x stops at AMIC5 */
			"DMIC0", "MIC BIAS1",
			"DMIC1", "MIC BIAS1",
			"DMIC2", "MIC BIAS3",
			"DMIC4", "MIC BIAS4",
			"SpkrLeft IN", "SPK1 OUT",
			"SpkrRight IN", "SPK2 OUT";

		mm1-dai-link {
			link-name = "MultiMedia1";
			cpu {
				sound-dai = <&q6asmdai MSM_FRONTEND_DAI_MULTIMEDIA1>;
			};
		};

		mm2-dai-link {
			link-name = "MultiMedia2";
			cpu {
				sound-dai = <&q6asmdai MSM_FRONTEND_DAI_MULTIMEDIA2>;
			};
		};

		mm3-dai-link {
			link-name = "MultiMedia3";
			cpu {
				sound-dai = <&q6asmdai MSM_FRONTEND_DAI_MULTIMEDIA3>;
			};
		};

		slim-dai-link {
			link-name = "SLIM Playback";
			cpu {
				sound-dai = <&q6afedai SLIMBUS_0_RX>;
			};
			platform {
				sound-dai = <&q6routing>;
			};
			codec {
				sound-dai = <&left_spkr>, <&right_spkr>, <&swm 0>, <&wcd9340 0>;
			};
		};

		slimcap-dai-link {
			link-name = "SLIM Capture";
			cpu {
				sound-dai = <&q6afedai SLIMBUS_0_TX>;
			};
			platform {
				sound-dai = <&q6routing>;
			};
			codec {
				sound-dai = <&wcd9340 1>;
			};
		};
	};
};

/*
 * CPU frequency scaling: CPRh closed-loop voltage plus OSM programming (out-of-tree
 * msm8998 port, patches 0031-0046): 300 MHz-1.9 GHz silver, 300 MHz-2.36 GHz gold,
 * delivered clock linear with the request. qcom-cpufreq-hw is a module so the OSM is
 * programmed after systemd arms the watchdog; OSM_STOP/CPRH_STOP in mk-boot-a.sh bisect.
 */
&apc_cprh {
	status = "okay";
};

&cpufreq_hw {
	status = "okay";
};

/*
 * Extra keys as the stock QX1000 tree has them: GPIO 21 (Fx logo key) is Super, GPIO 32/33
 * (yellow arrows, upstream "Super") are fn. fn reports RIGHTALT, the level-3 shift of the
 * "pro1" XKB layout (rootfs-overlay/etc/xkb/symbols/pro1), which carries the stock fn layer:
 * KEY_FN has no keysym, so compositors never saw it.
 */
&{/gpio-kb-extra-keys/key-home} {
	linux,code = <KEY_LEFTMETA>;
};

&{/gpio-kb-extra-keys/key-super-l} {
	linux,code = <KEY_RIGHTALT>;
};

&{/gpio-kb-extra-keys/key-super-r} {
	linux,code = <KEY_RIGHTALT>;
};

/*
 * APSS watchdog (downstream msm8998 qcom,msm-watchdog: 0x17817000, bark on SPI 3), fed by
 * systemd's RuntimeWatchdogSec: a hung SoC resets instead of waiting for the power key.
 */
&soc {
	watchdog@17817000 {
		compatible = "qcom,apss-wdt-msm8998", "qcom,kpss-wdt";
		reg = <0x17817000 0x1000>;
		clocks = <&sleep_clk>;
		interrupts = <GIC_SPI 3 IRQ_TYPE_EDGE_RISING>;
	};
};

/*
 * Notification LED: PMI8998 RGB tri-LED, LPG channels as stock msm-pmi8998.dtsi
 * (red pwm 5, green 4, blue 3), the OnePlus 6 layout.
 */
&pmi8998_lpg {
	status = "okay";

	multi-led {
		color = <LED_COLOR_ID_RGB>;
		function = LED_FUNCTION_STATUS;
		#address-cells = <1>;
		#size-cells = <0>;

		led@3 {
			reg = <3>;
			color = <LED_COLOR_ID_BLUE>;
		};

		led@4 {
			reg = <4>;
			color = <LED_COLOR_ID_GREEN>;
		};

		led@5 {
			reg = <5>;
			color = <LED_COLOR_ID_RED>;
		};
	};
};

/*
 * Vibrator: PMI8998 haptics, an LRA, stock msm-pmi8998.dtsi timing (6667 us = 150 Hz
 * play rate). Driver from the sdm845/sm8250 mainline ports (patch 0048, ff-memless,
 * buffer mode only).
 */
#include <dt-bindings/input/qcom,spmi-haptics.h>

&pmi8998_lsid1 {
	haptics@c000 {
		compatible = "qcom,pmi8998-haptics", "qcom,spmi-haptics";
		reg = <0xc000>;
		interrupts = <0x3 0xc0 0x0 IRQ_TYPE_EDGE_BOTH>,
			     <0x3 0xc0 0x1 IRQ_TYPE_EDGE_BOTH>;
		interrupt-names = "short", "play";
		qcom,actuator-type = <HAP_TYPE_LRA>;
		qcom,wave-shape = <HAP_WAVE_SQUARE>;	/* stock: "square" */
		qcom,play-mode = <HAP_PLAY_BUFFER>;
		qcom,wave-play-rate-us = <6667>;
		qcom,brake-pattern = <0x3 0x3 0x0 0x0>;
	};
};

/*
 * Sensors live behind the SLPI: FastRPC to its "sdsp" domain gives /dev/fastrpc-sdsp
 * for hexagonrpcd + libssc (postmarketOS sensor stack). sdm845 layout, without its
 * vmid/memory-region sharing.
 */
&remoteproc_slpi {
	glink-edge {
		fastrpc {
			compatible = "qcom,fastrpc";
			qcom,glink-channels = "fastrpcglink-apps-dsp";
			label = "sdsp";
			qcom,non-secure-domain;
			#address-cells = <1>;
			#size-cells = <0>;

			compute-cb@0 {
				compatible = "qcom,fastrpc-compute-cb";
				reg = <0>;
			};
		};
	};
};

/* ===== USB-C Type-C/PD (PMI8998, patch 0054) ===== */
#include <dt-bindings/usb/pd.h>
// SPDX-License-Identifier: GPL-2.0
/*
 * F(x)tec Pro1: PMI8998 Type-C + PD (TCPM, "qcom,pmi8998-typec") draft.
 * Append to msm8998-fxtec-pro1.dts (or kernel-patches/pro1-additions.dtsi).
 * Needs at the top of the board file:
 *   #include <dt-bindings/usb/pd.h>
 *
 * Replaces the stopgaps: the extcon on gpio38 (stock calls that pin
 * "qcom,usbplug-cc-gpio" and drives it from the DP driver, it is not an ID
 * pin) and the qcom_smbx orientation hook from patch 0052.
 */

/delete-node/ &extcon_usb;

&pmi8998_charger {
	/* TCPM drives the QMP PHY orientation now (connector port@1) */
	/delete-property/ orientation-switch;
};

&usb3_dwc3 {
	dr_mode = "otg";
	usb-role-switch;
	/delete-property/ extcon;

	port {
		usb3_dwc3_hs: endpoint {
			remote-endpoint = <&pmi8998_typec_hs_in>;
		};
	};
};

&usb3phy {
	orientation-switch;

	ports {
		#address-cells = <1>;
		#size-cells = <0>;

		/* port@0: output towards the connector */
		port@0 {
			reg = <0>;

			usb3phy_typec_ss: endpoint {
				remote-endpoint = <&pmi8998_typec_ss_in>;
			};
		};
	};
};

&pmi8998_lsid0 {
	pmi8998_typec: typec@1300 {
		compatible = "qcom,pmi8998-typec";
		/* SMB2 USBIN (Type-C state machine), PD PHY */
		reg = <0x1300>, <0x1700>;

		/* stock msm-pmi8998.dtsi: usb-chgpth@1300 irq 7, usb-pdphy@1700 */
		interrupts = <0x2 0x13 0x7 IRQ_TYPE_EDGE_RISING>,
			     <0x2 0x17 0x0 IRQ_TYPE_EDGE_RISING>,
			     <0x2 0x17 0x1 IRQ_TYPE_EDGE_RISING>,
			     <0x2 0x17 0x2 IRQ_TYPE_EDGE_RISING>,
			     <0x2 0x17 0x3 IRQ_TYPE_EDGE_RISING>,
			     <0x2 0x17 0x4 IRQ_TYPE_EDGE_RISING>,
			     <0x2 0x17 0x5 IRQ_TYPE_EDGE_RISING>,
			     <0x2 0x17 0x6 IRQ_TYPE_EDGE_RISING>;
		interrupt-names = "type-c-change",
				  "sig-tx",
				  "sig-rx",
				  "msg-tx",
				  "msg-rx",
				  "msg-tx-failed",
				  "msg-tx-discarded",
				  "msg-rx-discarded";

		/* stock: vdd-pdphy-supply = <&pm8998_l24> (shared with qusb2phy) */
		vdd-pdphy-supply = <&vreg_l24a_3p075>;

		connector {
			compatible = "usb-c-connector";
			/* DP alt mode HPD goes to this DP controller (typec displayport.c) */
			displayport = <&mdss_dp>;

			/*
			 * TODO: "dual" (and source-pdos + vbus-supply) once there is
			 * a PMI8998 OTG VBUS regulator; see NOTES.md. As a sink, DP
			 * alt mode needs a self-powered dock/hub, and TCPM must
			 * DR_Swap to host before it can enter the mode.
			 */
			power-role = "sink";
			data-role = "dual";
			self-powered;

			/* 5 V only: qcom_smbx does not follow PD contracts (ICL, HV) */
			sink-pdos = <PDO_FIXED(5000, 3000,
					       PDO_FIXED_USB_COMM |
					       PDO_FIXED_DATA_SWAP)>;
			op-sink-microwatt = <10000000>;

			altmodes {
				displayport {
					svid = /bits/ 16 <0xff01>;
					/* DFP_D, DP signalling, receptacle, pins C/D/E */
					vdo = <0x00001c46>;
				};
			};

			ports {
				#address-cells = <1>;
				#size-cells = <0>;

				port@0 {
					reg = <0>;

					pmi8998_typec_hs_in: endpoint {
						remote-endpoint = <&usb3_dwc3_hs>;
					};
				};

				port@1 {
					reg = <1>;

					pmi8998_typec_ss_in: endpoint {
						remote-endpoint = <&usb3phy_typec_ss>;
					};
				};

				port@2 {
					reg = <2>;

					pmi8998_typec_sbu_in: endpoint {
						remote-endpoint = <&usbc_sbu_mux_out>;
					};
				};

				/*
				 * TODO port@2 (SBU): the AUX/SBU switch is tlmm 77
				 * (stock "qcom,aux-en-gpio", driven 0 to enable, so
				 * active low) and tlmm 78 ("qcom,aux-sel-gpio", 1 for
				 * CC2/reversed), which maps to gpio-sbu-mux. Not
				 * enabled: the switch part number (needed for the
				 * compatible) is unknown, and a graph link to a node
				 * that never probes makes typec_register_port() defer
				 * forever. Sketch:
				 *
				 * port@2 {
				 *	reg = <2>;
				 *	pmi8998_typec_sbu_out: endpoint {
				 *		remote-endpoint = <&pro1_sbu_mux_in>;
				 *	};
				 * };
				 *
				 * / {
				 *	usb-sbu-mux {
				 *		compatible = "<vendor,part>", "gpio-sbu-mux";
				 *		enable-gpios = <&tlmm 77 GPIO_ACTIVE_LOW>;
				 *		select-gpios = <&tlmm 78 GPIO_ACTIVE_HIGH>;
				 *		mode-switch;
				 *		orientation-switch;
				 *		port {
				 *			pro1_sbu_mux_in: endpoint {
				 *				remote-endpoint = <&pmi8998_typec_sbu_out>;
				 *			};
				 *		};
				 *	};
				 * };
				 */
			};
		};
	};
};

/* ===== DisplayPort (patches 0055-0057) ===== */

/*
 * DisplayPort over USB-C: MSM8998 DP controller (0x0c990000) and the DP half
 * of the QMP USB3/DP PHY (patches 0001-0003 of msm8998-dp). Append after
 * pro1-additions.dtsi. Addresses, interrupt and AUX/lane settings are from
 * the vendor msm8998-mdss.dtsi / msm8998-mdss-pll.dtsi / msm8998.dtsi.
 *
 * DP alt mode itself (HPD) needs the PMI8998 Type-C/PD driver: its USB-C
 * connector node wants  displayport = <&mdss_dp>;  so the typec DP altmode
 * driver sends HPD to this controller (drm_connector_oob_hotplug_event).
 */
#include <dt-bindings/phy/phy-qcom-qmp.h>

&usb3phy {
	compatible = "qcom,msm8998-qmp-usb3-dp-phy";
	/* USB3 at +0, DP PHY +0x1000, DP TX0/TX1 +0x1400/+0x1800, DP PLL +0x1c00 */
	reg = <0x0c010000 0x2000>;
	#clock-cells = <1>;
	#phy-cells = <1>;
	/* vls_clamp, usb3_dp_phymode (vendor tcsr_usb3_dp_phymode @ 0x1fcb248) */
	qcom,tcsr-reg = <&tcsr_regs_2 0xb244 0xb248>;
};

&usb3_dwc3 {
	phys = <&qusb2phy>, <&usb3phy QMP_USB43DP_USB3_PHY>;
};

/* MMCC's "dplink"/"dpvco" inputs, <0> in msm8998.dtsi */
&mmcc {
	clocks = <&rpmcc RPM_SMD_XO_CLK_SRC>,
		 <&gcc GCC_MMSS_GPLL0_CLK>,
		 <&mdss_dsi0_phy DSI_PIXEL_PLL_CLK>,
		 <&mdss_dsi0_phy DSI_BYTE_PLL_CLK>,
		 <&mdss_dsi1_phy DSI_PIXEL_PLL_CLK>,
		 <&mdss_dsi1_phy DSI_BYTE_PLL_CLK>,
		 <&mdss_hdmi_phy>,
		 <&usb3phy QMP_USB43DP_DP_LINK_CLK>,
		 <&usb3phy QMP_USB43DP_DP_VCO_DIV_CLK>,
		 <&gcc GCC_MMSS_GPLL0_DIV_CLK>;
};

&mdss {
	/*
	 * ponytail: MDSS_HDMI_DP_AHB_CLK (vendor DP "core_alt_iface_clk") rides
	 * on the MDSS clocks, which msm_mdss enables as a bulk; dp_ctrl has no
	 * slot for it. Upgrade path: an optional core clock in dp_ctrl.
	 */
	clocks = <&mmcc MDSS_AHB_CLK>,
		 <&mmcc MDSS_AXI_CLK>,
		 <&mmcc MDSS_MDP_CLK>,
		 <&mmcc MDSS_HDMI_DP_AHB_CLK>;
	clock-names = "iface",
		      "bus",
		      "core",
		      "dp_ahb";

	mdss_dp: displayport-controller@c990000 {
		compatible = "qcom,msm8998-dp";
		/* vendor: one 0xa84 region; same sub-block layout as sdm845 */
		reg = <0x0c990000 0x200>,
		      <0x0c990200 0x200>,
		      <0x0c990400 0x600>,
		      <0x0c990a00 0x84>;

		interrupt-parent = <&mdss>;
		interrupts = <12>;

		clocks = <&mmcc MDSS_AHB_CLK>,
			 <&mmcc MDSS_DP_AUX_CLK>,
			 <&mmcc MDSS_DP_LINK_CLK>,
			 <&mmcc MDSS_DP_LINK_INTF_CLK>,
			 <&mmcc MDSS_DP_PIXEL_CLK>;
		clock-names = "core_iface",
			      "core_aux",
			      "ctrl_link",
			      "ctrl_link_iface",
			      "stream_pixel";

		assigned-clocks = <&mmcc DP_LINK_CLK_SRC>,
				  <&mmcc DP_PIXEL_CLK_SRC>;
		assigned-clock-parents = <&usb3phy QMP_USB43DP_DP_LINK_CLK>,
					 <&usb3phy QMP_USB43DP_DP_VCO_DIV_CLK>;

		phys = <&usb3phy QMP_USB43DP_DP_PHY>;
		phy-names = "dp";

		operating-points-v2 = <&dp_opp_table>;
		power-domains = <&rpmpd RPMPD_VDDCX>;

		#sound-dai-cells = <0>;

		ports {
			#address-cells = <1>;
			#size-cells = <0>;

			port@0 {
				reg = <0>;

				mdss_dp_in: endpoint {
					remote-endpoint = <&dpu_intf0_out>;
				};
			};

			port@1 {
				reg = <1>;

				mdss_dp_out: endpoint {
					/* vendor qcom,logical2physical-lane-map = [02 03 01 00] */
					data-lanes = <1 0>;	/* 2 lanes (fit pin C and D); <0 1> trained every lane but never aligned (DPCD 0x204 = 0) */
					link-frequencies = /bits/ 64 <1620000000 2700000000 5400000000>;
				};
			};
		};

		/* vendor dp_link_clk_src VDD_DIG_FMAX_MAP3(LOWER, LOW, NOMINAL) */
		dp_opp_table: opp-table {
			compatible = "operating-points-v2";

			opp-162000000 {
				opp-hz = /bits/ 64 <162000000>;
				required-opps = <&rpmpd_opp_low_svs>;
			};

			opp-270000000 {
				opp-hz = /bits/ 64 <270000000>;
				required-opps = <&rpmpd_opp_svs>;
			};

			opp-540000000 {
				opp-hz = /bits/ 64 <540000000>;
				required-opps = <&rpmpd_opp_nom>;
			};
		};
	};
};

&mdss_mdp {
	ports {
		port@3 {
			reg = <3>;

			dpu_intf0_out: endpoint {
				remote-endpoint = <&mdss_dp_in>;
			};
		};
	};
};

/*
 * DP AUX rides the USB-C SBU pins through a switch: stock mdss_dp drives
 * aux-en (tlmm 77) low to enable and aux-sel (tlmm 78) high for a CC2 plug.
 * gpio-sbu-mux enables it only in DP alt mode and selects by orientation.
 */
/ {
	usbc_sbu_mux: usbc-sbu-mux {
		compatible = "pericom,pi3usb102", "gpio-sbu-mux";
		enable-gpios = <&tlmm 77 GPIO_ACTIVE_LOW>;
		select-gpios = <&tlmm 78 GPIO_ACTIVE_HIGH>;
		mode-switch;
		orientation-switch;

		port {
			usbc_sbu_mux_out: endpoint {
				remote-endpoint = <&pmi8998_typec_sbu_in>;
			};
		};
	};
};
